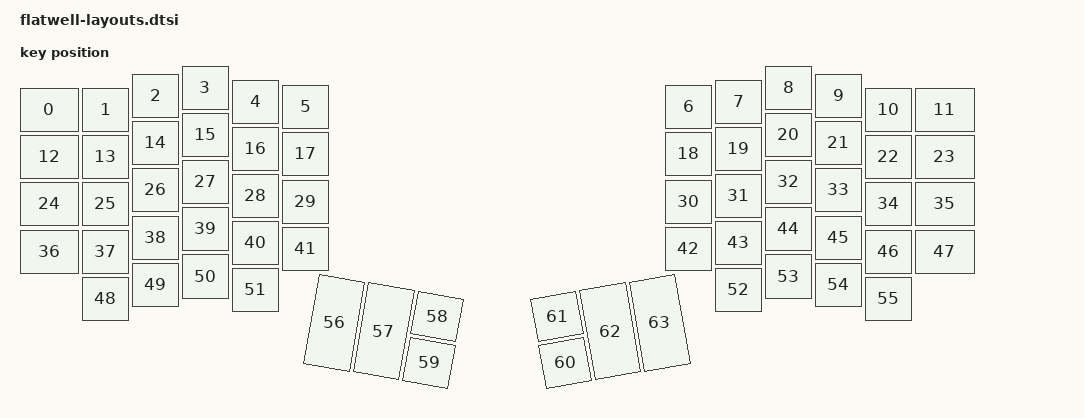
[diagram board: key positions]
// Generated by scripts/zmk.mjs. Edit that (or ergogen/config.yaml), not this file.

#include <physical_layouts.dtsi>

/ {
    physical_layout0: physical_layout_0 {
        compatible = "zmk,physical-layout";
        display-name = "Flatwell";
        transform = <&default_transform>;
        kscan = <&kscan0>;

        keys  //                     w    h       x       y     rot      rx      ry
            = <&key_physical_attrs  125   94      53      97       0     115     144>  // =
            , <&key_physical_attrs  100   94     178      97       0     228     144>  // 1
            , <&key_physical_attrs  100   94     278      69       0     328     117>  // 2
            , <&key_physical_attrs  100   94     378      53       0     428     100>  // 3
            , <&key_physical_attrs  100   94     478      81       0     528     128>  // 4
            , <&key_physical_attrs  100   94     578      92       0     628     139>  // 5
            , <&key_physical_attrs  100   94    1344      92       0    1394     139>  // 6
            , <&key_physical_attrs  100   94    1444      81       0    1494     128>  // 7
            , <&key_physical_attrs  100   94    1544      53       0    1594     100>  // 8
            , <&key_physical_attrs  100   94    1644      69       0    1694     117>  // 9
            , <&key_physical_attrs  100   94    1744      97       0    1794     144>  // 0
            , <&key_physical_attrs  125   94    1844      97       0    1907     144>  // -
            , <&key_physical_attrs  125   94      53     192       0     115     239>  // Tab
            , <&key_physical_attrs  100   94     178     192       0     228     239>  // Q
            , <&key_physical_attrs  100   94     278     164       0     328     211>  // W
            , <&key_physical_attrs  100   94     378     147       0     428     194>  // E
            , <&key_physical_attrs  100   94     478     175       0     528     222>  // R
            , <&key_physical_attrs  100   94     578     186       0     628     233>  // T
            , <&key_physical_attrs  100   94    1344     186       0    1394     233>  // Y
            , <&key_physical_attrs  100   94    1444     175       0    1494     222>  // U
            , <&key_physical_attrs  100   94    1544     147       0    1594     194>  // I
            , <&key_physical_attrs  100   94    1644     164       0    1694     211>  // O
            , <&key_physical_attrs  100   94    1744     192       0    1794     239>  // P
            , <&key_physical_attrs  125   94    1844     192       0    1907     239>  // \
            , <&key_physical_attrs  125   94      53     286       0     115     333>  // Esc
            , <&key_physical_attrs  100   94     178     286       0     228     333>  // A
            , <&key_physical_attrs  100   94     278     258       0     328     306>  // S
            , <&key_physical_attrs  100   94     378     242       0     428     289>  // D
            , <&key_physical_attrs  100   94     478     269       0     528     317>  // F
            , <&key_physical_attrs  100   94     578     281       0     628     328>  // G
            , <&key_physical_attrs  100   94    1344     281       0    1394     328>  // H
            , <&key_physical_attrs  100   94    1444     269       0    1494     317>  // J
            , <&key_physical_attrs  100   94    1544     242       0    1594     289>  // K
            , <&key_physical_attrs  100   94    1644     258       0    1694     306>  // L
            , <&key_physical_attrs  100   94    1744     286       0    1794     333>  // ;
            , <&key_physical_attrs  125   94    1844     286       0    1907     333>  // '
            , <&key_physical_attrs  125   94      53     381       0     115     428>  // Shift
            , <&key_physical_attrs  100   94     178     381       0     228     428>  // Z
            , <&key_physical_attrs  100   94     278     353       0     328     400>  // X
            , <&key_physical_attrs  100   94     378     336       0     428     383>  // C
            , <&key_physical_attrs  100   94     478     364       0     528     411>  // V
            , <&key_physical_attrs  100   94     578     375       0     628     422>  // B
            , <&key_physical_attrs  100   94    1344     375       0    1394     422>  // N
            , <&key_physical_attrs  100   94    1444     364       0    1494     411>  // M
            , <&key_physical_attrs  100   94    1544     336       0    1594     383>  // ,
            , <&key_physical_attrs  100   94    1644     353       0    1694     400>  // .
            , <&key_physical_attrs  100   94    1744     381       0    1794     428>  // /
            , <&key_physical_attrs  125   94    1844     381       0    1907     428>  // Shift
            , <&key_physical_attrs  100   94     178     475       0     228     522>  // `
            , <&key_physical_attrs  100   94     278     447       0     328     494>  // Fn
            , <&key_physical_attrs  100   94     378     431       0     428     478>  // ←
            , <&key_physical_attrs  100   94     478     458       0     528     506>  // →
            , <&key_physical_attrs  100   94    1444     458       0    1494     506>  // ↑
            , <&key_physical_attrs  100   94    1544     431       0    1594     478>  // ↓
            , <&key_physical_attrs  100   94    1644     447       0    1694     494>  // [
            , <&key_physical_attrs  100   94    1744     475       0    1794     522>  // ]
            , <&key_physical_attrs  100  189     636     476    1000     686     570>  // Bksp
            , <&key_physical_attrs  100  189     734     493    1000     784     588>  // Del
            , <&key_physical_attrs  100   94     841     511    1000     891     558>  // Ctrl
            , <&key_physical_attrs  100   94     825     604    1000     875     651>  // End
            , <&key_physical_attrs  100   94    1097     604 (-1000)    1147     651>  // PgDn
            , <&key_physical_attrs  100   94    1081     511 (-1000)    1131     558>  // Ctrl
            , <&key_physical_attrs  100  189    1188     493 (-1000)    1238     588>  // Enter
            , <&key_physical_attrs  100  189    1286     476 (-1000)    1336     570>  // Space
            ;
    };
};
